AUTOSAR XML
package /polyarchos/Interfaces
  4 x sender receiver interface:
    FuelInjectionIf  # Fuel Injection Control Interface
    EngineSpeedIf  # Engine Speed Sensor Interface
    BrakePressureIf  # Brake Pressure Actuator Interface
    WheelSpeedIf  # Wheel Speed Sensor Interface
  port interface ObjectDetectionIf  # Object Detection Service Interface (Adaptive)
  port interface LaneFusionIf  # Lane Fusion Service Interface (Adaptive)
package /polyarchos/Classic
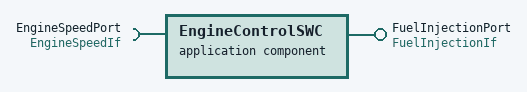
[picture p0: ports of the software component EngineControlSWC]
  application sw component type EngineControlSWC  # Engine Control Software Component
    provide port FuelInjectionPort: provided-interface=FuelInjectionIf
    require port EngineSpeedPort: required-interface=EngineSpeedIf
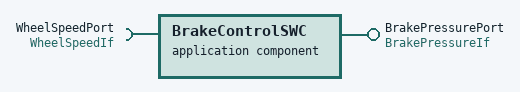
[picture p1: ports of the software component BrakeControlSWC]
  application sw component type BrakeControlSWC  # Brake Control Software Component
    provide port BrakePressurePort: provided-interface=BrakePressureIf
    require port WheelSpeedPort: required-interface=WheelSpeedIf
  sensor actuator sw component type WheelSpeedSensorSWC  # Wheel Speed Sensor Abstraction SWC
    provide port WheelSpeedOut: provided-interface=WheelSpeedIf
package /polyarchos/Adaptive
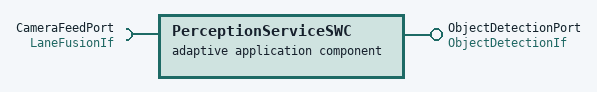
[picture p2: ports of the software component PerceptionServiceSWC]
  adaptive application sw component type PerceptionServiceSWC  # Perception Service Software Component (ADAS)
    provide port ObjectDetectionPort: provided-interface=ObjectDetectionIf
    require port CameraFeedPort: required-interface=LaneFusionIf
